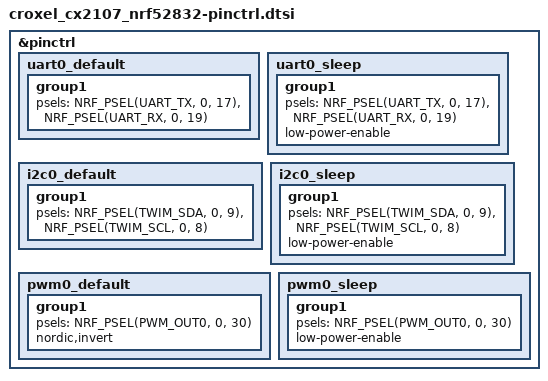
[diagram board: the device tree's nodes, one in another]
/*
 * Copyright (c) 2022 Nordic Semiconductor
 * SPDX-License-Identifier: Apache-2.0
 */

&pinctrl {
	uart0_default: uart0_default {
		group1 {
			psels = <NRF_PSEL(UART_TX, 0, 17)>,
				<NRF_PSEL(UART_RX, 0, 19)>;
		};
	};

	uart0_sleep: uart0_sleep {
		group1 {
			psels = <NRF_PSEL(UART_TX, 0, 17)>,
				<NRF_PSEL(UART_RX, 0, 19)>;
			low-power-enable;
		};
	};
	i2c0_default: i2c0_default {
		group1 {
			psels = <NRF_PSEL(TWIM_SDA, 0, 9)>,
				<NRF_PSEL(TWIM_SCL, 0, 8)>;
		};
	};

	i2c0_sleep: i2c0_sleep {
		group1 {
			psels = <NRF_PSEL(TWIM_SDA, 0, 9)>,
				<NRF_PSEL(TWIM_SCL, 0, 8)>;
			low-power-enable;
		};
	};

	pwm0_default: pwm0_default {
		group1 {
			psels = <NRF_PSEL(PWM_OUT0, 0, 30)>;
			nordic,invert;
		};
	};

	pwm0_sleep: pwm0_sleep {
		group1 {
			psels = <NRF_PSEL(PWM_OUT0, 0, 30)>;
			low-power-enable;
		};
	};
};
